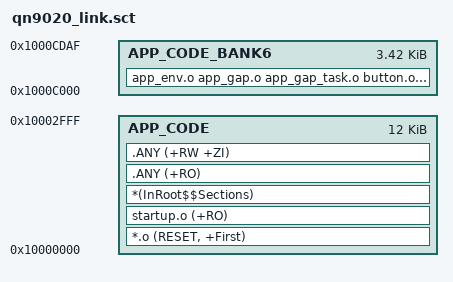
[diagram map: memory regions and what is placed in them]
; *************************************************************
; *** Scatter-Loading Description File generated by Quintic ***
; *************************************************************

LR_ROM1 0x10000000 0xCDB0
{
    APP_CODE 0x10000000 0x3000
    {
        *.o (RESET, +First)
        startup.o (+RO)
        *(InRoot$$Sections)
        .ANY (+RO)
        .ANY (+RW +ZI)
    }

    APP_CODE_BANK6  0x1000c000 0xDB0
    {
        app_env.o app_gap.o app_gap_task.o button.o app_smp_task.o app_task.o app_util.o prf_utils.o wdt.o system.o timer.o usr_design.o gpio.o led.o (+RO)
    }
}

